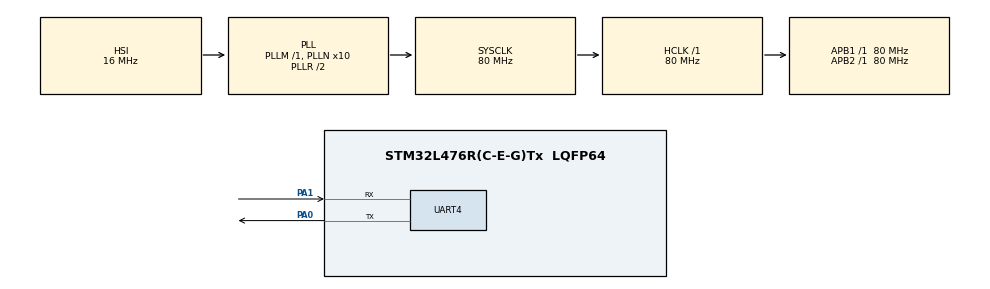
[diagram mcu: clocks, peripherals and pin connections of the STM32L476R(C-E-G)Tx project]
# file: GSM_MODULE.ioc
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Mcu.Family=STM32L4
Mcu.Name=STM32L476R(C-E-G)Tx
Mcu.Package=LQFP64
NVIC.PriorityGroup=NVIC_PRIORITYGROUP_4
NVIC.UART4_IRQn=true\:0\:0\:false\:false\:true\:true\:true\:true
PA0.Mode=Asynchronous
PA0.Signal=UART4_TX
PA1.Mode=Asynchronous
PA1.Signal=UART4_RX
ProjectManager.HeapSize=0x200
ProjectManager.StackSize=0x400
ProjectManager.TargetToolchain=STM32CubeIDE
RCC.ADCFreq_Value=64000000
RCC.AHBFreq_Value=80000000
RCC.APB1Freq_Value=80000000
RCC.APB1TimFreq_Value=80000000
RCC.APB2Freq_Value=80000000
RCC.APB2TimFreq_Value=80000000
RCC.CortexFreq_Value=80000000
RCC.HCLKFreq_Value=80000000
RCC.HSE_VALUE=8000000
RCC.HSI_VALUE=16000000
RCC.MSI_VALUE=4000000
RCC.PLLN=10
RCC.PLLSourceVirtual=RCC_PLLSOURCE_HSI
RCC.PREFETCH_ENABLE=1
RCC.SYSCLKFreq_VALUE=80000000
RCC.SYSCLKSource=RCC_SYSCLKSOURCE_PLLCLK
RCC.USBFreq_Value=64000000
RCC.VCOOutputFreq_Value=160000000
board=NUCLEO-L476RG

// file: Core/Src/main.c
/* USER CODE BEGIN Header */
/**
  ******************************************************************************
  * @file           : main.c
  * @brief          : Main program body
  ******************************************************************************
  * @attention
  *
  * Copyright (c) 2024 STMicroelectronics.
  * All rights reserved.
  *
  * This software is licensed under terms that can be found in the LICENSE file
  * in the root directory of this software component.
  * If no LICENSE file comes with this software, it is provided AS-IS.
  *
  ******************************************************************************
  */
/* USER CODE END Header */
#include "main.h"
#include "main.h"
#include "stdio.h"
#include "string.h"
#define RXSIZE 100
uint8_t RxBuf[RXSIZE];
char *Rx_string;
uint8_t state=0;
uint8_t substate=0;
int _write(int file,char *ptr,int len)
{
    int i=0;
    for(i=0;i<len;i++)
    	ITM_SendChar((*ptr++));
    return len;
}

UART_HandleTypeDef huart4;

/* USER CODE BEGIN PV */
/*void HAL_UART_TxCpltCallback(UART_HandleTypeDef *huart)
{

  HAL_UART_Receive_IT(&huart4, RxBuf, 1000);
}*/
/* USER CODE END PV */

void SystemClock_Config(void);
static void MX_GPIO_Init(void);
static void MX_UART4_Init(void);
/* USER CODE BEGIN PFP */
char* GSM_Send_AT_Command(char* AT_CMD)
{
	memset(RxBuf,0,sizeof(RxBuf));
	HAL_UART_Transmit_IT(&huart4,(uint8_t*)AT_CMD, strlen(AT_CMD));
	HAL_UART_Receive(&huart4, RxBuf, 100,10);
	printf("Received data %s\n",RxBuf);
	return (char *)RxBuf;

}
/* USER CODE END PFP */

int main(void)
{

  /* MCU Configuration--------------------------------------------------------*/

  /* Reset of all peripherals, Initializes the Flash interface and the Systick. */
  HAL_Init();

  /* Configure the system clock */
  SystemClock_Config();

  /* Initialize all configured peripherals */
  MX_GPIO_Init();
  MX_UART4_Init();
  /* USER CODE BEGIN 2 */
  /*
  HAL_UART_Transmit_IT(&huart4,(uint8_t *)"ATE0\r\n", sizeof("ATE0\r\n"));
  HAL_UART_Receive(&huart4, RxBuf, 100,10);
  printf("Received data %s\n",RxBuf);
  memset(RxBuf,0,sizeof(RxBuf));
  //HAL_Delay(1000);
  HAL_UART_Transmit_IT(&huart4,(uint8_t *)"AT+CSQ\r\n", sizeof("AT+CSQ\r\n"));
  HAL_UART_Receive(&huart4, RxBuf, 100,10);
  memset(RxBuf,0,sizeof(RxBuf));
 //// printf("Received data %s\n",RxBuf);
 // memset(RxBuf,0,100);
  printf("Completed\n");
 // memset(RxBuf,0,100);*/
  /* USER CODE END 2 */

  /* Infinite loop */
  while (1)
  {
	  switch(state)
	  {
	  case 1:
	  {
		  switch(substate)
  		  {
  		  case 0:
  			  Rx_string = GSM_Send_AT_Command("ATE0\r");
  			  if(!(strncmp(Rx_string,"\r\nOK\r\n",6)))
  			  {
  				 state=1;
  			  }
  			  else
  			  {
  				  subsstate=1;
  			  }
  			  break;
  		  case 1:
  			  if(!(strncmp(Rx_string,"\r\nERROR\r\n",6)))
  			  {
  			  	  subsstate=0;
  			  }
  			  else
  			  {
  			  	  state=0;
  			  }
  			  break;
  		  default:
  			  break;

  	}

  }
}

void SystemClock_Config(void)
{
  RCC_OscInitTypeDef RCC_OscInitStruct = {0};
  RCC_ClkInitTypeDef RCC_ClkInitStruct = {0};

  /** Configure the main internal regulator output voltage
  */
  if (HAL_PWREx_ControlVoltageScaling(PWR_REGULATOR_VOLTAGE_SCALE1) != HAL_OK)
  {
    Error_Handler();
  }

  /** Initializes the RCC Oscillators according to the specified parameters
  * in the RCC_OscInitTypeDef structure.
  */
  RCC_OscInitStruct.OscillatorType = RCC_OSCILLATORTYPE_HSI;
  RCC_OscInitStruct.HSIState = RCC_HSI_ON;
  RCC_OscInitStruct.HSICalibrationValue = RCC_HSICALIBRATION_DEFAULT;
  RCC_OscInitStruct.PLL.PLLState = RCC_PLL_ON;
  RCC_OscInitStruct.PLL.PLLSource = RCC_PLLSOURCE_HSI;
  RCC_OscInitStruct.PLL.PLLM = 1;
  RCC_OscInitStruct.PLL.PLLN = 10;
  RCC_OscInitStruct.PLL.PLLP = RCC_PLLP_DIV7;
  RCC_OscInitStruct.PLL.PLLQ = RCC_PLLQ_DIV2;
  RCC_OscInitStruct.PLL.PLLR = RCC_PLLR_DIV2;
  if (HAL_RCC_OscConfig(&RCC_OscInitStruct) != HAL_OK)
  {
    Error_Handler();
  }

  /** Initializes the CPU, AHB and APB buses clocks
  */
  RCC_ClkInitStruct.ClockType = RCC_CLOCKTYPE_HCLK|RCC_CLOCKTYPE_SYSCLK
                              |RCC_CLOCKTYPE_PCLK1|RCC_CLOCKTYPE_PCLK2;
  RCC_ClkInitStruct.SYSCLKSource = RCC_SYSCLKSOURCE_PLLCLK;
  RCC_ClkInitStruct.AHBCLKDivider = RCC_SYSCLK_DIV1;
  RCC_ClkInitStruct.APB1CLKDivider = RCC_HCLK_DIV1;
  RCC_ClkInitStruct.APB2CLKDivider = RCC_HCLK_DIV1;

  if (HAL_RCC_ClockConfig(&RCC_ClkInitStruct, FLASH_LATENCY_4) != HAL_OK)
  {
    Error_Handler();
  }
}

static void MX_UART4_Init(void)
{

  huart4.Instance = UART4;
  huart4.Init.BaudRate = 115200;
  huart4.Init.WordLength = UART_WORDLENGTH_8B;
  huart4.Init.StopBits = UART_STOPBITS_1;
  huart4.Init.Parity = UART_PARITY_NONE;
  huart4.Init.Mode = UART_MODE_TX_RX;
  huart4.Init.HwFlowCtl = UART_HWCONTROL_NONE;
  huart4.Init.OverSampling = UART_OVERSAMPLING_16;
  huart4.Init.OneBitSampling = UART_ONE_BIT_SAMPLE_DISABLE;
  huart4.AdvancedInit.AdvFeatureInit = UART_ADVFEATURE_NO_INIT;
  if (HAL_UART_Init(&huart4) != HAL_OK)
  {
    Error_Handler();
  }

}

static void MX_GPIO_Init(void)
{

  /* GPIO Ports Clock Enable */
  __HAL_RCC_GPIOA_CLK_ENABLE();

}

void Error_Handler(void)
{
  __disable_irq();
  while (1)
  {
  }
}
